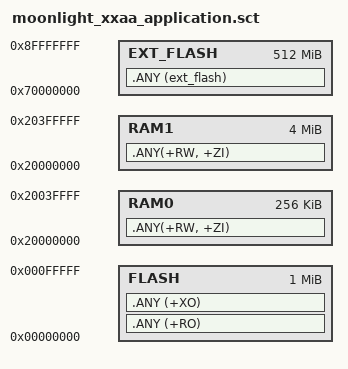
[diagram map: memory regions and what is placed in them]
LOAD 0x00000000 0x00100000
{
    FLASH 0x00000000 0x00100000
    {
    
        .ANY (+RO)
        .ANY (+XO)
    }
    EXT_FLASH 0x70000000 0x20000000
    {
    .ANY (ext_flash) ; Data or code allocated to external memory 
    }
    RAM0 0x20000000 0x00040000
    {
    .ANY(+RW, +ZI) ; RW data and ZI data
    }

    RAM1 0x20000000 0x00400000
    {
    .ANY(+RW, +ZI) ; RW data and ZI data
    }

}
